# ATSAM4E16E device description
Architecture: CORTEX-M4; Family: SAM4; Series: SAM4E
Registers are 32-bit, read-write, no defined reset value unless marked. A register's access mark holds for its fields unless they carry their own. Offsets are from the block's base; [hi:lo] are bit positions; {n}, {i} and the like mark numbered series; 'fields as' and 'values as' point back to an identical list.

## TC — Timer Counter
Instances: TC0 0x40090000, TC1 0x40094000, TC2 0x40098000
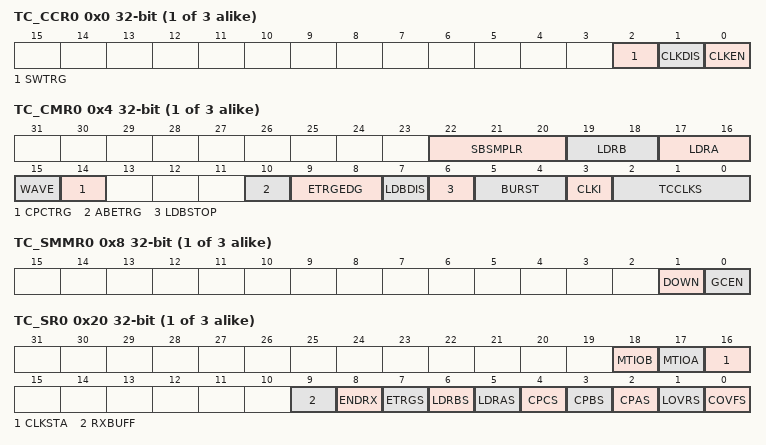
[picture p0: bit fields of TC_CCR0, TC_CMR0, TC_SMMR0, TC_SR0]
{0x0+0x40*i} TC_CCR{i} wo (i=0..2) — Channel Control Register (channel = {i})
  [2] SWTRG — Software Trigger Command
  [1] CLKDIS — Counter Clock Disable Command
  [0] CLKEN — Counter Clock Enable Command
{0x4+0x40*i} TC_CMR{i} (i=0..2) — Channel Mode Register (channel = {i})
  [22:20] SBSMPLR — Loading Edge Subsampling Ratio
    0=ONE (Load a Capture Register each selected edge); 1=HALF (Load a Capture Register every 2 selected edges); 2=FOURTH (Load a Capture Register every 4 selected edges); 3=EIGHTH (Load a Capture Register every 8 selected edges); 4=SIXTEENTH (Load a Capture Register every 16 selected edges)
  [19:18] LDRB — RB Loading Edge Selection
    0=NONE; 1=RISING (Rising edge of TIOA); 2=FALLING (Falling edge of TIOA); 3=EDGE (Each edge of TIOA)
  [17:16] LDRA — RA Loading Edge Selection
    values as LDRB
  [15] WAVE — Waveform Mode
  [14] CPCTRG — RC Compare Trigger Enable
  [10] ABETRG — TIOA or TIOB External Trigger Selection
  [9:8] ETRGEDG — External Trigger Edge Selection
    0=NONE (The clock is not gated by an external signal.); 1=RISING (Rising edge); 2=FALLING (Falling edge); 3=EDGE (Each edge)
  [7] LDBDIS — Counter Clock Disable with RB Loading
  [6] LDBSTOP — Counter Clock Stopped with RB Loading
  [5:4] BURST — Burst Signal Selection
    0=NONE (The clock is not gated by an external signal.); 1=XC0 (XC0 is ANDed with the selected clock.); 2=XC1 (XC1 is ANDed with the selected clock.); 3=XC2 (XC2 is ANDed with the selected clock.)
  [3] CLKI — Clock Invert
  [2:0] TCCLKS — Clock Selection
    {v}=TIMER_CLOCK{v+1} (Clock selected: TCLK{v+1}) (v=0..4); 5=XC0 (Clock selected: XC0); 6=XC1 (Clock selected: XC1); 7=XC2 (Clock selected: XC2)
{0x8+0x40*i} TC_SMMR{i} (i=0..2) — Stepper Motor Mode Register (channel = {i})
  [1] DOWN — DOWN Count
  [0] GCEN — Gray Count Enable
{0xC+0x40*i} TC_RAB{i} ro (i=0..2) — Register AB (channel = {i})
  [31:0] RAB — Register A or Register B
{0x10+0x40*i} TC_CV{i} ro (i=0..2) — Counter Value (channel = {i})
  [31:0] CV — Counter Value
{0x14+0x40*i} TC_RA{i} (i=0..2) — Register A (channel = {i})
  [31:0] RA — Register A
{0x18+0x40*i} TC_RB{i} (i=0..2) — Register B (channel = {i})
  [31:0] RB — Register B
{0x1C+0x40*i} TC_RC{i} (i=0..2) — Register C (channel = {i})
  [31:0] RC — Register C
{0x20+0x40*i} TC_SR{i} ro (i=0..2) — Status Register (channel = {i})
  [18] MTIOB — TIOB Mirror
  [17] MTIOA — TIOA Mirror
  [16] CLKSTA — Clock Enabling Status
  [9] RXBUFF — Reception Buffer Full
  [8] ENDRX — End of Receiver Transfer
  [7] ETRGS — External Trigger Status
  [6] LDRBS — RB Loading Status
  [5] LDRAS — RA Loading Status
  [4] CPCS — RC Compare Status
  [3] CPBS — RB Compare Status
  [2] CPAS — RA Compare Status
  [1] LOVRS — Load Overrun Status
  [0] COVFS — Counter Overflow Status
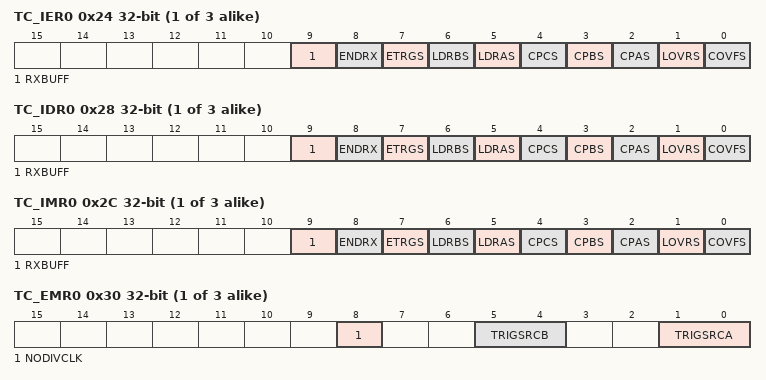
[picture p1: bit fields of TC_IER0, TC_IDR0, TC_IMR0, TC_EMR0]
{0x24+0x40*i} TC_IER{i} wo (i=0..2) — Interrupt Enable Register (channel = {i})
  [9] RXBUFF — Reception Buffer Full
  [8] ENDRX — End of Receiver Transfer
  [7] ETRGS — External Trigger
  [6] LDRBS — RB Loading
  [5] LDRAS — RA Loading
  [4] CPCS — RC Compare
  [3] CPBS — RB Compare
  [2] CPAS — RA Compare
  [1] LOVRS — Load Overrun
  [0] COVFS — Counter Overflow
{0x28+0x40*i} TC_IDR{i} wo (i=0..2) — Interrupt Disable Register (channel = {i})
  fields as TC_IER0
{0x2C+0x40*i} TC_IMR{i} ro (i=0..2) — Interrupt Mask Register (channel = {i})
  fields as TC_IER0
{0x30+0x40*i} TC_EMR{i} (i=0..2) — Extended Mode Register (channel = {i})
  [8] NODIVCLK — NO DIVided CLocK
  [5:4] TRIGSRCB — TRIGger SouRCe for input B
    0=EXTERNAL_TIOBx (the trigger/capture input B is driven by external pin TIOBx); 1=PWMx (the trigger/capture input B is driven internally by PWMx)
  [1:0] TRIGSRCA — TRIGger SouRCe for input A
    0=EXTERNAL_TIOAx (the trigger/capture input A is driven by external pin TIOAx); 1=PWMx (the trigger/capture input A is driven internally by PWMx)
0xC0 TC_BCR wo — Block Control Register
  [0] SYNC — Synchro Command
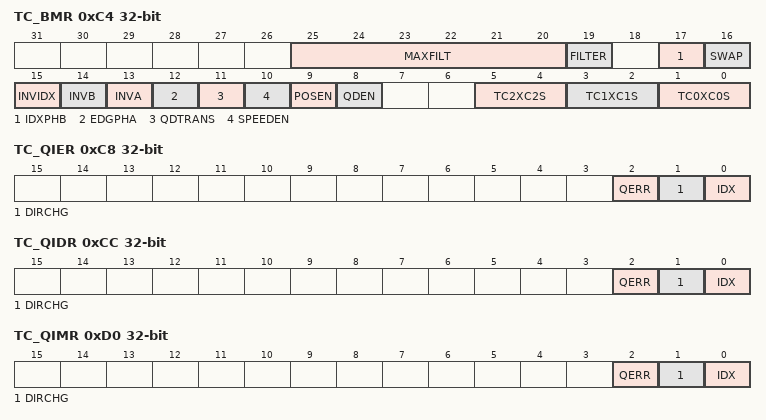
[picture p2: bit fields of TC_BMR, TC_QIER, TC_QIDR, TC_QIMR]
0xC4 TC_BMR — Block Mode Register
  [25:20] MAXFILT — MAXimum FILTer
  [19] FILTER
  [17] IDXPHB — InDeX pin is PHB pin
  [16] SWAP — SWAP PHA and PHB
  [15] INVIDX — INVerted InDeX
  [14] INVB — INVerted phB
  [13] INVA — INVerted phA
  [12] EDGPHA — EDGe on PHA count mode
  [11] QDTRANS — Quadrature Decoding TRANSparent
  [10] SPEEDEN — SPEED ENabled
  [9] POSEN — POSition ENabled
  [8] QDEN — Quadrature Decoder ENabled
  [5:4] TC2XC2S — External Clock Signal 2 Selection
    0=TCLK2 (Signal connected to XC2: TCLK2); 2=TIOA1 (Signal connected to XC2: TIOA1); 3=TIOA2 (Signal connected to XC2: TIOA2)
  [3:2] TC1XC1S — External Clock Signal 1 Selection
    0=TCLK1 (Signal connected to XC1: TCLK1); 2=TIOA0 (Signal connected to XC1: TIOA0); 3=TIOA2 (Signal connected to XC1: TIOA2)
  [1:0] TC0XC0S — External Clock Signal 0 Selection
    0=TCLK0 (Signal connected to XC0: TCLK0); 2=TIOA1 (Signal connected to XC0: TIOA1); 3=TIOA2 (Signal connected to XC0: TIOA2)
0xC8 TC_QIER wo — QDEC Interrupt Enable Register
  [2] QERR — Quadrature ERRor
  [1] DIRCHG — DIRection CHanGe
  [0] IDX — InDeX
0xCC TC_QIDR wo — QDEC Interrupt Disable Register
  fields as TC_QIER
0xD0 TC_QIMR ro — QDEC Interrupt Mask Register
  fields as TC_QIER
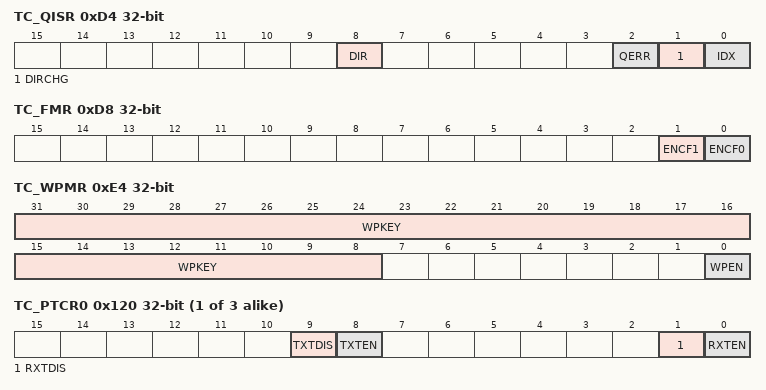
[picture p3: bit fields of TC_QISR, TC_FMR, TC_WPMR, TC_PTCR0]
0xD4 TC_QISR ro — QDEC Interrupt Status Register
  [8] DIR — DIRection
  [2] QERR — Quadrature ERRor
  [1] DIRCHG — DIRection CHanGe
  [0] IDX — InDeX
0xD8 TC_FMR — Fault Mode Register
  [1] ENCF1 — ENable Compare Fault Channel 1
  [0] ENCF0 — ENable Compare Fault Channel 0
0xE4 TC_WPMR — Write Protect Mode Register
  [31:8] WPKEY — Write Protect KEY
  [0] WPEN — Write Protect Enable
{0x100+0x40*i} TC_RPR{i} (i=0..2) — Receive Pointer Register (pdc = {i})
  [31:0] RXPTR — Receive Pointer Register
{0x104+0x40*i} TC_RCR{i} (i=0..2) — Receive Counter Register (pdc = {i})
  [15:0] RXCTR — Receive Counter Register
{0x110+0x40*i} TC_RNPR{i} (i=0..2) — Receive Next Pointer Register (pdc = {i})
  [31:0] RXNPTR — Receive Next Pointer
{0x114+0x40*i} TC_RNCR{i} (i=0..2) — Receive Next Counter Register (pdc = {i})
  [15:0] RXNCTR — Receive Next Counter
{0x120+0x40*i} TC_PTCR{i} wo (i=0..2) — Transfer Control Register (pdc = {i})
  [9] TXTDIS — Transmitter Transfer Disable
  [8] TXTEN — Transmitter Transfer Enable
  [1] RXTDIS — Receiver Transfer Disable
  [0] RXTEN — Receiver Transfer Enable
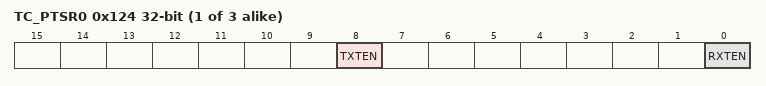
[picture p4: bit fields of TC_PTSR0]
{0x124+0x40*i} TC_PTSR{i} ro (i=0..2) — Transfer Status Register (pdc = {i})
  [8] TXTEN — Transmitter Transfer Enable
  [0] RXTEN — Receiver Transfer Enable
